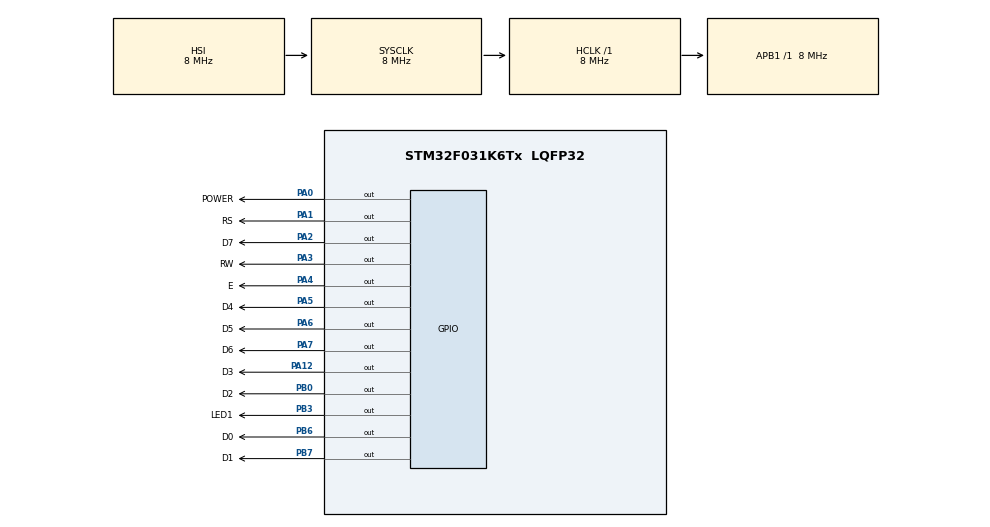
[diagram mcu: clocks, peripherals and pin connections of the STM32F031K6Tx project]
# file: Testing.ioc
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Mcu.Family=STM32F0
Mcu.Name=STM32F031K6Tx
Mcu.Package=LQFP32
PA0.GPIO_Label=POWER
PA0.GPIO_PuPd=GPIO_PULLUP
PA0.PinState=GPIO_PIN_SET
PA0.Signal=GPIO_Output
PA1.GPIO_Label=RS
PA1.Signal=GPIO_Output
PA12.GPIO_Label=D3
PA12.Signal=GPIO_Output
PA13.Mode=Serial_Wire
PA13.Signal=SYS_SWDIO
PA14.Mode=Serial_Wire
PA14.Signal=SYS_SWCLK
PA2.GPIO_Label=D7
PA2.Signal=GPIO_Output
PA3.GPIO_Label=RW
PA3.Signal=GPIO_Output
PA4.GPIO_Label=E
PA4.Signal=GPIO_Output
PA5.GPIO_Label=D4
PA5.Signal=GPIO_Output
PA6.GPIO_Label=D5
PA6.Signal=GPIO_Output
PA7.GPIO_Label=D6
PA7.Signal=GPIO_Output
PB0.GPIO_Label=D2
PB0.Signal=GPIO_Output
PB3.GPIO_Label=LED1
PB3.Signal=GPIO_Output
PB6.GPIO_Label=D0
PB6.Signal=GPIO_Output
PB7.GPIO_Label=D1
PB7.Signal=GPIO_Output
ProjectManager.HeapSize=0x200
ProjectManager.StackSize=0x400
ProjectManager.TargetToolchain=STM32CubeIDE
RCC.AHBFreq_Value=8000000
RCC.APB1Freq_Value=8000000
RCC.APB1TimFreq_Value=8000000
RCC.HCLKFreq_Value=8000000
RCC.SYSCLKFreq_VALUE=8000000
board=custom

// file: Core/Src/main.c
/* USER CODE BEGIN Header */
/**
  ******************************************************************************
  * @file           : main.c
  * @brief          : Main program body
  ******************************************************************************
  * @attention
  *
  * Copyright (c) 2024 STMicroelectronics.
  * All rights reserved.
  *
  * This software is licensed under terms that can be found in the LICENSE file
  * in the root directory of this software component.
  * If no LICENSE file comes with this software, it is provided AS-IS.
  *
  ******************************************************************************
  */
/* USER CODE END Header */
#include "main.h"

void SystemClock_Config(void);
static void MX_GPIO_Init(void);

int main(void)
{

  /* MCU Configuration--------------------------------------------------------*/

  /* Reset of all peripherals, Initializes the Flash interface and the Systick. */
  HAL_Init();

  /* Configure the system clock */
  SystemClock_Config();

  /* Initialize all configured peripherals */
  MX_GPIO_Init();
  /* USER CODE BEGIN 2 */

  LCD_Init();
  Play_Debug_Sequence();
  Play_Celebration_Lyrics();

  /* USER CODE END 2 */

  /* Infinite loop */
  while (1)
  {

    /* USER CODE BEGIN 3 */

	  HAL_GPIO_TogglePin(LED1_GPIO_Port, LED1_Pin);
	  HAL_Delay(500);
  }

  /* USER CODE END 3 */
}

void SystemClock_Config(void)
{
  RCC_OscInitTypeDef RCC_OscInitStruct = {0};
  RCC_ClkInitTypeDef RCC_ClkInitStruct = {0};

  /** Initializes the RCC Oscillators according to the specified parameters
  * in the RCC_OscInitTypeDef structure.
  */
  RCC_OscInitStruct.OscillatorType = RCC_OSCILLATORTYPE_HSI;
  RCC_OscInitStruct.HSIState = RCC_HSI_ON;
  RCC_OscInitStruct.HSICalibrationValue = RCC_HSICALIBRATION_DEFAULT;
  RCC_OscInitStruct.PLL.PLLState = RCC_PLL_NONE;
  if (HAL_RCC_OscConfig(&RCC_OscInitStruct) != HAL_OK)
  {
    Error_Handler();
  }

  /** Initializes the CPU, AHB and APB buses clocks
  */
  RCC_ClkInitStruct.ClockType = RCC_CLOCKTYPE_HCLK|RCC_CLOCKTYPE_SYSCLK
                              |RCC_CLOCKTYPE_PCLK1;
  RCC_ClkInitStruct.SYSCLKSource = RCC_SYSCLKSOURCE_HSI;
  RCC_ClkInitStruct.AHBCLKDivider = RCC_SYSCLK_DIV1;
  RCC_ClkInitStruct.APB1CLKDivider = RCC_HCLK_DIV1;

  if (HAL_RCC_ClockConfig(&RCC_ClkInitStruct, FLASH_LATENCY_0) != HAL_OK)
  {
    Error_Handler();
  }
}

static void MX_GPIO_Init(void)
{
  GPIO_InitTypeDef GPIO_InitStruct = {0};

  /* GPIO Ports Clock Enable */
  __HAL_RCC_GPIOA_CLK_ENABLE();
  __HAL_RCC_GPIOB_CLK_ENABLE();

  /*Configure GPIO pin Output Level */
  HAL_GPIO_WritePin(POWER_GPIO_Port, POWER_Pin, GPIO_PIN_SET);

  /*Configure GPIO pin Output Level */
  HAL_GPIO_WritePin(GPIOA, RS_Pin|D7_Pin|RW_Pin|E_Pin
                          |D4_Pin|D5_Pin|D6_Pin|D3_Pin, GPIO_PIN_RESET);

  /*Configure GPIO pin Output Level */
  HAL_GPIO_WritePin(GPIOB, D2_Pin|LED1_Pin|D0_Pin|D1_Pin, GPIO_PIN_RESET);

  /*Configure GPIO pin : POWER_Pin */
  GPIO_InitStruct.Pin = POWER_Pin;
  GPIO_InitStruct.Mode = GPIO_MODE_OUTPUT_PP;
  GPIO_InitStruct.Pull = GPIO_PULLUP;
  GPIO_InitStruct.Speed = GPIO_SPEED_FREQ_LOW;
  HAL_GPIO_Init(POWER_GPIO_Port, &GPIO_InitStruct);

  /*Configure GPIO pins : RS_Pin D7_Pin RW_Pin E_Pin
                           D4_Pin D5_Pin D6_Pin D3_Pin */
  GPIO_InitStruct.Pin = RS_Pin|D7_Pin|RW_Pin|E_Pin
                          |D4_Pin|D5_Pin|D6_Pin|D3_Pin;
  GPIO_InitStruct.Mode = GPIO_MODE_OUTPUT_PP;
  GPIO_InitStruct.Pull = GPIO_NOPULL;
  GPIO_InitStruct.Speed = GPIO_SPEED_FREQ_LOW;
  HAL_GPIO_Init(GPIOA, &GPIO_InitStruct);

  /*Configure GPIO pins : D2_Pin LED1_Pin D0_Pin D1_Pin */
  GPIO_InitStruct.Pin = D2_Pin|LED1_Pin|D0_Pin|D1_Pin;
  GPIO_InitStruct.Mode = GPIO_MODE_OUTPUT_PP;
  GPIO_InitStruct.Pull = GPIO_NOPULL;
  GPIO_InitStruct.Speed = GPIO_SPEED_FREQ_LOW;
  HAL_GPIO_Init(GPIOB, &GPIO_InitStruct);

}

void Error_Handler(void)
{
  __disable_irq();
  while (1)
  {
  }
}
